# STM32MP13xx register map
File version: 1.5
CPU: CA7 r0p0, little endian, MPU, FPU, 4 interrupt priority bits
Registers are 32-bit, read-write, reset 0x0 unless marked. A register's access mark holds for its fields unless they carry their own. Offsets are from the block's base; [hi:lo] are bit positions; {n}, {i} and the like mark numbered series.

## ETZPC
Base 0x5C007000
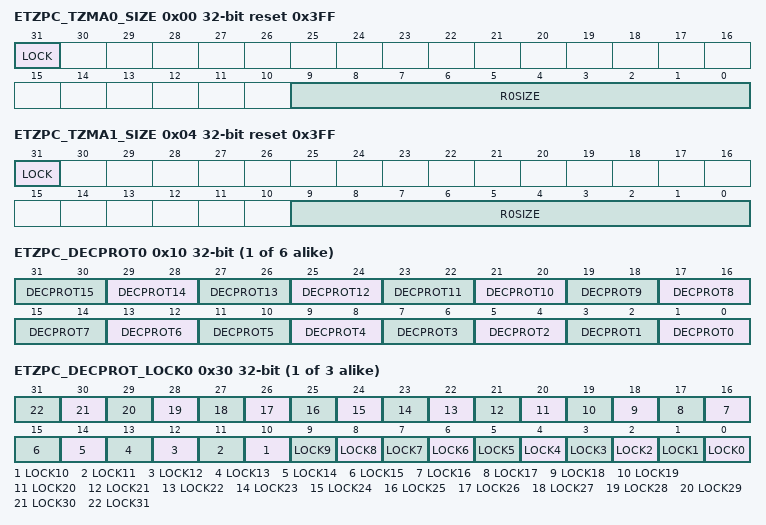
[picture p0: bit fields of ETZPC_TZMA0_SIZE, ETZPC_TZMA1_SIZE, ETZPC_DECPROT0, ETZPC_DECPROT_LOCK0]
0x00 ETZPC_TZMA0_SIZE reset 0x3FF — ETZPC ROM secure size definition
  [31] LOCK, [9:0] R0SIZE
0x04 ETZPC_TZMA1_SIZE reset 0x3FF — ETZPC RAM secure size definition
  [31] LOCK, [9:0] R0SIZE
{0x10+4i} ETZPC_DECPROT{i} (i=0..5) — Register reset values
  [2n+1:2n] DECPROT{n} (n=0..15)
{0x30+4i} ETZPC_DECPROT_LOCK{i} (i=0..2)
  [n] LOCK{n} (n=0..31)
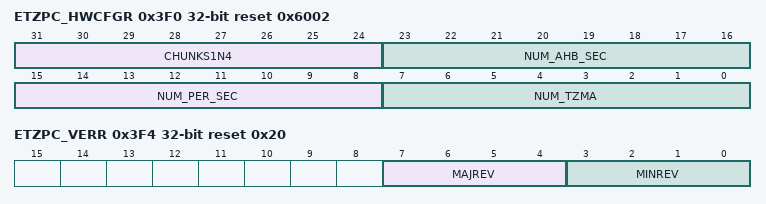
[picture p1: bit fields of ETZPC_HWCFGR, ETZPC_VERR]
0x3F0 ETZPC_HWCFGR ro reset 0x6002 — ETZPC IP HW configuration register
  [31:24] CHUNKS1N4, [23:16] NUM_AHB_SEC, [15:8] NUM_PER_SEC, [7:0] NUM_TZMA
0x3F4 ETZPC_VERR ro reset 0x20 — ETZPC IP version register
  [7:4] MAJREV, [3:0] MINREV
0x3F8 ETZPC_IDR ro reset 0x100061 — ETZPC IP version register
  [31:0] ID
0x3FC ETZPC_SIDR ro reset 0xA3C5DD01 — ETZPC IP version register
  [31:0] SID

## HDP — HDP register block
Base 0x5002A000
0x00 HDP_CTRL — HDP control register
  [0] EN — Enable HDP Valid if enabled in BSEC.
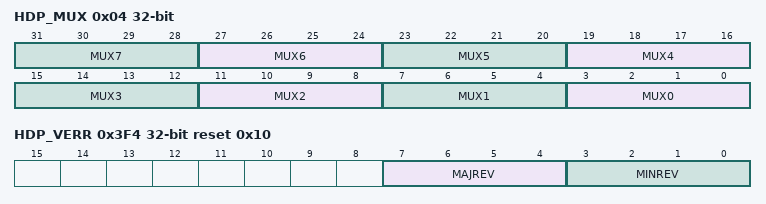
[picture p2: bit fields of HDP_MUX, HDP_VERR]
0x04 HDP_MUX — HDP multiplexers control register
  [4n+3:4n] MUX{n} (n=0..7) — Select the HDP{n} output among the 16 available signals
0x10 HDP_VAL ro — HDP read back value register
  [7:0] HDPVAL — HDP read back value Provides the value of the HDP signals.
0x14 HDP_GPOSET wo reset not defined — HDP general purpose output set register
  [7:0] HDPGPOSET — HDP general purpose output set When a bit is written to 1, the corresponding HDP GPO is set. Writing a bit to 0 has no effect.
0x18 HDP_GPOCLR wo reset not defined — HDP general purpose output clear register
  [7:0] HDPGPOCLR — HDP general purpose output clear When a bit is written to 1, the corresponding HDP GPO is cleared. Writing a bit to 0 has no effect.
0x1C HDP_GPOVAL — HDP general purpose output value register
  [7:0] HDPGPOVAL — HDP general purpose output value When written, defines the value of the HDP GPO. When read, provides the current GPO value.
0x3F4 HDP_VERR ro reset 0x10 — HDP version register
  [7:4] MAJREV — Major revision of the IP
  [3:0] MINREV — Minor revision of the IP
0x3F8 HDP_IPIDR ro reset 0x30002 — HDP IP identification register
  [31:0] ID — IP Identifier
0x3FC HDP_SIDR ro reset 0xA3C5DD01 — HDP size identification register
  [31:0] SID — Size identifier

## IWDG1
Base 0x5C003000
Same registers: IWDG2 0x5A002000
0x00 IWDG_KR wo — Key register
  [15:0] KEY
0x04 IWDG_PR reset 0x7 — Prescaler register
  [2:0] PR
0x08 IWDG_RLR reset 0xFFF — Reload register
  [11:0] RL
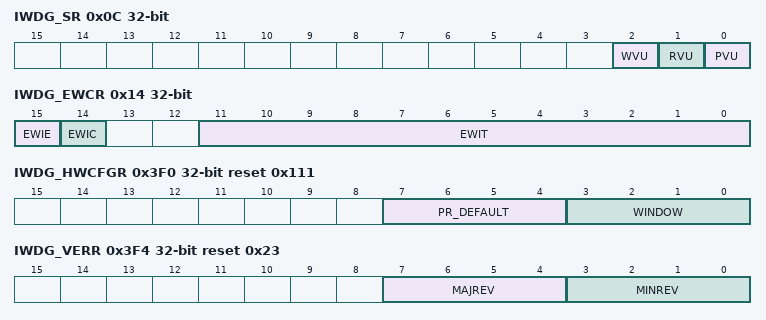
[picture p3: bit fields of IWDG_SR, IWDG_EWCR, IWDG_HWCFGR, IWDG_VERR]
0x0C IWDG_SR ro — Status register
  [2] WVU, [1] RVU, [0] PVU
0x10 IWDG_WINR reset 0xFFF — Window register
  [11:0] WIN
0x14 IWDG_EWCR — IWDG early wake-up interrupt register
  [15] EWIE, [14] EWIC, [11:0] EWIT
0x3F0 IWDG_HWCFGR ro reset 0x111 — IWDG hardware configuration register
  [7:4] PR_DEFAULT, [3:0] WINDOW
0x3F4 IWDG_VERR ro reset 0x23 — IWDG version register
  [7:4] MAJREV, [3:0] MINREV
0x3F8 IWDG_IDR ro reset 0x120041 — IWDG identification register
  [31:0] ID
0x3FC IWDG_SIDR ro reset 0xA3C5DD01 — IWDG size identification register
  [31:0] SID

## MDMA
Base 0x58000000
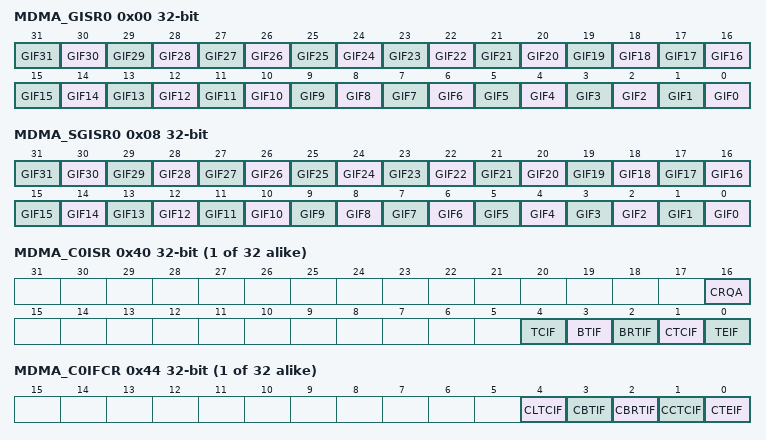
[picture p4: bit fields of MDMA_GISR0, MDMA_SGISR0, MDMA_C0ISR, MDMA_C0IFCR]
0x00 MDMA_GISR0 ro — MDMA global interrupt/status register
  [n] GIF{n} (n=0..31)
0x08 MDMA_SGISR0 ro — MDMA secure global interrupt/status register
  [n] GIF{n} (n=0..31)
{0x40+0x40*i} MDMA_C{i}ISR ro (i=0..31) — MDMA channel {i} interrupt/status register
  [16] CRQA, [4] TCIF, [3] BTIF, [2] BRTIF, [1] CTCIF, [0] TEIF
{0x44+0x40*i} MDMA_C{i}IFCR wo (i=0..31) — MDMA channel {i} interrupt flag clear register
  [4] CLTCIF, [3] CBTIF, [2] CBRTIF, [1] CCTCIF, [0] CTEIF
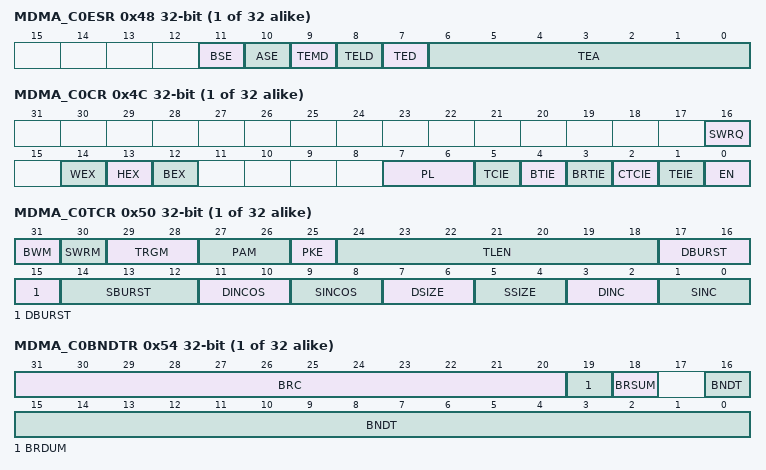
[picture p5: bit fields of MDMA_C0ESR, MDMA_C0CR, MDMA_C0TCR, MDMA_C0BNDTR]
{0x48+0x40*i} MDMA_C{i}ESR ro (i=0..31) — MDMA channel {i} error status register
  [11] BSE, [10] ASE, [9] TEMD, [8] TELD, [7] TED, [6:0] TEA
{0x4C+0x40*i} MDMA_C{i}CR access per field (i=0..31) — This register is used to control the concerned channel.
  [16] SWRQ wo, [14] WEX rw, [13] HEX rw, [12] BEX rw, [7:6] PL rw, [5] TCIE rw, [4] BTIE rw, [3] BRTIE rw, [2] CTCIE rw, [1] TEIE rw, [0] EN rw
{0x50+0x40*i} MDMA_C{i}TCR (i=0..31) — This register is used to configure the concerned channel. In Linked List mode, at the end of a block (single or last block in repeated block transfer mode), this register will be loaded from memory (from address given by current LAR[31:0] + 0x00).
  [31] BWM, [30] SWRM, [29:28] TRGM, [27:26] PAM, [25] PKE, [24:18] TLEN, [17:15] DBURST, [14:12] SBURST, [11:10] DINCOS, [9:8] SINCOS, [7:6] DSIZE, [5:4] SSIZE, [3:2] DINC, [1:0] SINC
{0x54+0x40*i} MDMA_C{i}BNDTR (i=0..31) — In Linked List mode, at the end of a block (single or last block in repeated block transfer mode), this register will be loaded from memory (from address given by current LAR[31:0] + 0x04).
  [31:20] BRC, [19] BRDUM, [18] BRSUM, [16:0] BNDT
{0x58+0x40*i} MDMA_C{i}SAR (i=0..31) — In Linked List mode, at the end of a Block (single or last Block in repeated Block transfer mode), this register will be loaded from memory (from address given by current LAR[31:0] + 0x08).
  [31:0] SAR
{0x5C+0x40*i} MDMA_C{i}DAR (i=0..31) — In Linked List mode, at the end of a block (single or last block in repeated block transfer mode), this register will be loaded from memory (from address given by current LAR[31:0] + 0x0C). M
  [31:0] DAR
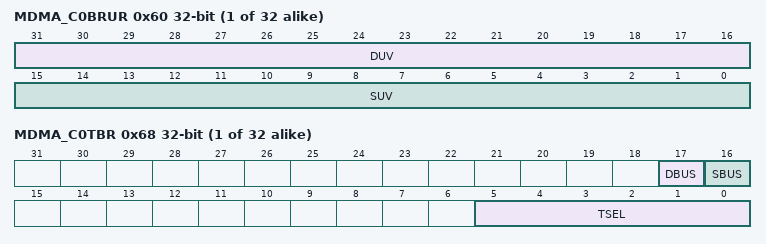
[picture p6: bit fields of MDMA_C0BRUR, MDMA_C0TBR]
{0x60+0x40*i} MDMA_C{i}BRUR (i=0..31) — In Linked List mode, at the end of a block (single or last block in repeated block transfer mode), this register will be loaded from memory (from address given by current LAR[31:0] + 0x10).
  [31:16] DUV, [15:0] SUV
{0x64+0x40*i} MDMA_C{i}LAR (i=0..31) — In Linked List mode, at the end of a block (single or last block in repeated block transfer mode), this register will be loaded from memory (from address given by current LAR[31:0] + 0x14). The new value is only taken into account after all registers are updated, for the next end of block.
  [31:0] LAR
{0x68+0x40*i} MDMA_C{i}TBR (i=0..31) — In Linked List mode, at the end of a block (single or last block in repeated block transfer mode), this register will be loaded from memory (from address given by current LAR[31:0] + 0x18).
  [17] DBUS, [16] SBUS, [5:0] TSEL
{0x70+0x40*i} MDMA_C{i}MAR (i=0..31) — In Linked List mode, at the end of a block (single or last block in repeated block transfer mode), this register will be loaded from memory (from address given by current LAR[31:0] + 0x20).
  [31:0] MAR
{0x74+0x40*i} MDMA_C{i}MDR (i=0..31) — In Linked List mode, at the end of a block (single or last block in repeated block transfer mode), this register will be loaded from memory (from address given by current LAR[31:0] + 0x24).
  [31:0] MDR
